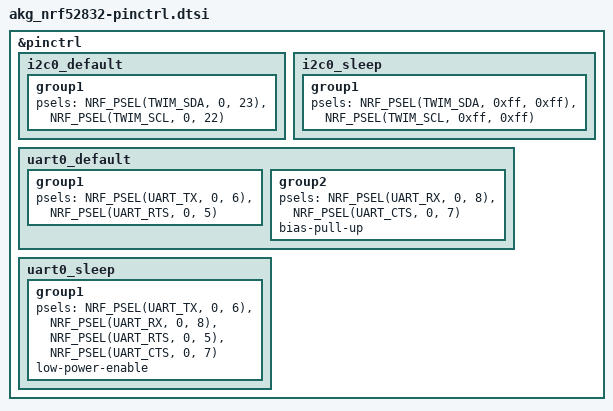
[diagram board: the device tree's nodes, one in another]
&pinctrl {
    i2c0_default: i2c0_default {
        group1 {
            psels = <NRF_PSEL(TWIM_SDA, 0, 23)>,
                    <NRF_PSEL(TWIM_SCL, 0, 22)>;
        };
    };

    i2c0_sleep: i2c0_sleep {
        group1 {
            psels = <NRF_PSEL(TWIM_SDA, 0xff, 0xff)>,
                    <NRF_PSEL(TWIM_SCL, 0xff, 0xff)>;
        };
    };

    uart0_default: uart0_default {
		group1 {
			psels = <NRF_PSEL(UART_TX, 0, 6)>,
				<NRF_PSEL(UART_RTS, 0, 5)>;
		};
		group2 {
			psels = <NRF_PSEL(UART_RX, 0, 8)>,
				<NRF_PSEL(UART_CTS, 0, 7)>;
			bias-pull-up;
		};
	};

	uart0_sleep: uart0_sleep {
		group1 {
			psels = <NRF_PSEL(UART_TX, 0, 6)>,
				<NRF_PSEL(UART_RX, 0, 8)>,
				<NRF_PSEL(UART_RTS, 0, 5)>,
				<NRF_PSEL(UART_CTS, 0, 7)>;
			low-power-enable;
		};
    };
};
